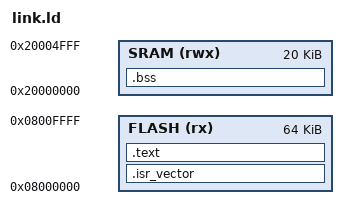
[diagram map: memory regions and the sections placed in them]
/* STM32F103C8T6 linker script */

MEMORY
{
    FLASH (rx)  : ORIGIN = 0x08000000, LENGTH = 64K
    SRAM  (rwx) : ORIGIN = 0x20000000, LENGTH = 20K
}

/* Stack starts at the top of SRAM */
_estack = ORIGIN(SRAM) + LENGTH(SRAM);

ENTRY(Reset_Handler)

SECTIONS
{
    /* Vector table must be first in Flash */
    .isr_vector :
    {
        . = ALIGN(4);
        KEEP(*(.isr_vector))
        . = ALIGN(4);
    } > FLASH

    /* Code and read-only data */
    .text :
    {
        . = ALIGN(4);
        *(.text*)
        *(.rodata*)
        . = ALIGN(4);
    } > FLASH

    /* Uninitialized data (zeroed by startup) */
    .bss :
    {
        . = ALIGN(4);
        _sbss = .;
        *(.bss*)
        *(COMMON)
        . = ALIGN(4);
        _ebss = .;
    } > SRAM
}
